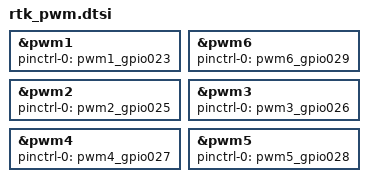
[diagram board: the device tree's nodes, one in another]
/* Copyright 2025 The ChromiumOS Authors
 * Use of this source code is governed by a BSD-style license that can be
 * found in the LICENSE file.
 */

/* Keyboard backlight - use a prescaler for operation about 324 Hz */
&pwm1 {
	status = "okay";
	pinctrl-0 = <&pwm1_gpio023>;
	pinctrl-names = "default";
};

/* Fan - use a separate prescaler for Fan, b:358312912 */
&pwm6 {
	status = "okay";
	pinctrl-0 = <&pwm6_gpio029>;
	pinctrl-names = "default";
};

/* Board LEDs - share one prescaler reference, all clocks must be configured
 * for 324 Hz or lower so LEDs work in low power mode.
 */
&pwm2 {
	status = "okay";
	pinctrl-0 = <&pwm2_gpio025>;
	pinctrl-names = "default";
};

&pwm3 {
	status = "okay";
	pinctrl-0 = <&pwm3_gpio026>;
	pinctrl-names = "default";
};

&pwm4 {
	status = "okay";
	pinctrl-0 = <&pwm4_gpio027>;
	pinctrl-names = "default";
};

&pwm5 {
	status = "okay";
	pinctrl-0 = <&pwm5_gpio028>;
	pinctrl-names = "default";
};
